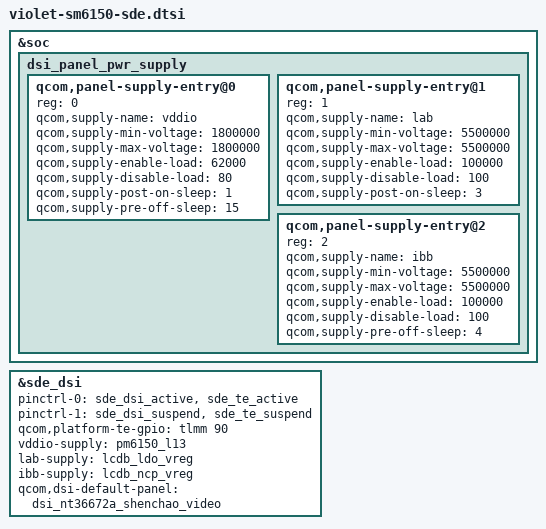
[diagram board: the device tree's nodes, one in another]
// SPDX-License-Identifier: GPL-2.0-only
#include "sm6150-sde.dtsi"

&soc {
	dsi_panel_pwr_supply: dsi_panel_pwr_supply {
		#address-cells = <1>;
		#size-cells = <0>;

		/* 4.14 sm6150 values with the violet sleeps */
		qcom,panel-supply-entry@0 {
			reg = <0>;
			qcom,supply-name = "vddio";
			qcom,supply-min-voltage = <1800000>;
			qcom,supply-max-voltage = <1800000>;
			qcom,supply-enable-load = <62000>;
			qcom,supply-disable-load = <80>;
			qcom,supply-post-on-sleep = <1>;
			qcom,supply-pre-off-sleep = <15>;
		};

		qcom,panel-supply-entry@1 {
			reg = <1>;
			qcom,supply-name = "lab";
			/* the 5.5 V the bootloader sets, which 4.14 kept: see the commit */
			qcom,supply-min-voltage = <5500000>;
			qcom,supply-max-voltage = <5500000>;
			qcom,supply-enable-load = <100000>;
			qcom,supply-disable-load = <100>;
			qcom,supply-post-on-sleep = <3>;
		};

		qcom,panel-supply-entry@2 {
			reg = <2>;
			qcom,supply-name = "ibb";
			/* the 5.5 V the bootloader sets, which 4.14 kept: see the commit */
			qcom,supply-min-voltage = <5500000>;
			qcom,supply-max-voltage = <5500000>;
			qcom,supply-enable-load = <100000>;
			qcom,supply-disable-load = <100>;
			qcom,supply-pre-off-sleep = <4>;
		};
	};
};

&sde_dsi {
	pinctrl-names = "panel_active", "panel_suspend";
	pinctrl-0 = <&sde_dsi_active &sde_te_active>;
	pinctrl-1 = <&sde_dsi_suspend &sde_te_suspend>;

	qcom,platform-te-gpio = <&tlmm 90 0>;

	vddio-supply = <&pm6150_l13>;
	lab-supply = <&lcdb_ldo_vreg>;
	ibb-supply = <&lcdb_ncp_vreg>;
	qcom,dsi-default-panel = <&dsi_nt36672a_shenchao_video>;
};
